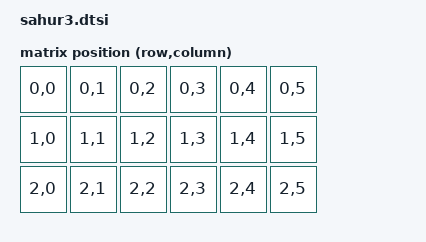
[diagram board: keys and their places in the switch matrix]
// This file was generated from a template. Edit it to match your keyboard.
// See https://zmk.dev/docs/development/hardware-integration/new-shield for more
// instructions.

#include <dt-bindings/zmk/matrix_transform.h>

#include "sahur3-layouts.dtsi"

/ {
    chosen {
        zmk,physical-layout = &physical_layout0;
    };

    kscan0: kscan0 {
        // If the hardware does not use a switch matrix, change this to the
        // appropriate driver and update the properties below to match.
        // See https://zmk.dev/docs/config/kscan for supported key scan drivers.
        compatible = "zmk,kscan-gpio-matrix";
        // Set this to "col2row" or "row2col" to match the hardware. If using
        // "row2col", change the col-gpios in the _left.overlay and _right.overlay
        // files to (GPIO_ACTIVE_HIGH | GPIO_PULL_DOWN) and the row-gpios here to
        // GPIO_ACTIVE_HIGH.
        diode-direction = "row2col";
        wakeup-source;


    };

    default_transform: keymap_transform0 {
        compatible = "zmk,matrix-transform";
        columns = <6>;
        rows = <3>;
        map = <
        //  LKey 1 |LKey 2 |LKey 3 LKey 4 |LKey 5 |LKey 6
            RC(0,0) RC(0,1) RC(0,2) RC(0,3) RC(0,4) RC(0,5)
        //  LKey 7 |LKey 8 |LKey 9 LKey 10 |LKey 11 |LKey 12
            RC(1,0) RC(1,1) RC(1,2) RC(1,3) RC(1,4) RC(1,5)
        //  LKey 13 |LKey 14 |LKey 15 LKey 16 |LKey 17 |LKey 18
            RC(2,0) RC(2,1) RC(2,2) RC(2,3) RC(2,4) RC(2,5)
        >;
    };
};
